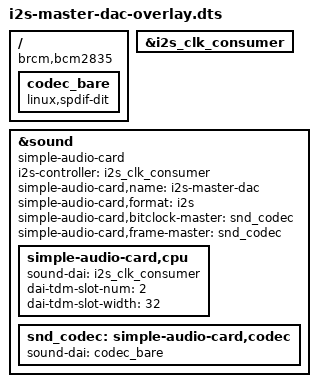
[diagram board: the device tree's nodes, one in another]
// Definitions for a generic I2S DAC that acts as clock master on the bus.
/dts-v1/;
/plugin/;

/ {
	compatible = "brcm,bcm2835";

	fragment@0 {
		target = <&i2s_clk_consumer>;
		__overlay__ {
			status = "okay";
		};
	};

	fragment@1 {
		target-path = "/";
		__overlay__ {
			codec_bare: codec_bare {
				compatible = "linux,spdif-dit";
				#sound-dai-cells = <0>;
				status = "okay";
			};
		};
	};

	fragment@2 {
		target = <&sound>;
		__overlay__ {
			compatible = "simple-audio-card";
			i2s-controller = <&i2s_clk_consumer>;
			status = "okay";

			simple-audio-card,name = "i2s-master-dac";
			simple-audio-card,format = "i2s";

			simple-audio-card,bitclock-master = <&snd_codec>;
			simple-audio-card,frame-master = <&snd_codec>;

			simple-audio-card,cpu {
				sound-dai = <&i2s_clk_consumer>;
				dai-tdm-slot-num = <2>;
				dai-tdm-slot-width = <32>;
			};

			snd_codec: simple-audio-card,codec {
				sound-dai = <&codec_bare>;
			};
		};
	};
};
